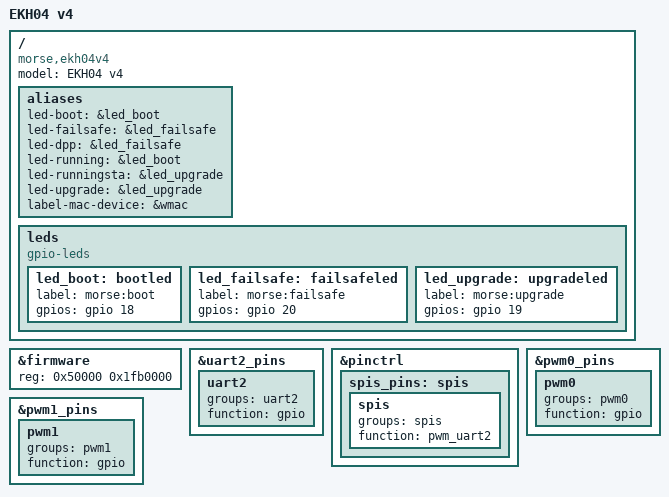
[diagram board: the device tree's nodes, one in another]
#include "mt7628an_morse_ekh03.dtsi"

/ {
	compatible = "morse,ekh04v4", "mediatek,mt7628an-soc";
	model = "EKH04 v4";

	aliases {
		led-boot = &led_boot;
		led-failsafe = &led_failsafe;
		led-dpp = &led_failsafe;
		led-running = &led_boot;
		led-runningsta = &led_upgrade;
		led-upgrade = &led_upgrade;
		label-mac-device = &wmac;
	};

	leds {
		compatible = "gpio-leds";

		led_boot: bootled {
			label = "morse:boot";
			gpios = <&gpio 18 GPIO_ACTIVE_HIGH>;
		};

		led_failsafe: failsafeled {
			label = "morse:failsafe";
			gpios = <&gpio 20 GPIO_ACTIVE_HIGH>;
		};

		led_upgrade: upgradeled {
			label = "morse:upgrade";
			gpios = <&gpio 19 GPIO_ACTIVE_HIGH>;
		};
	};
};

&firmware {
	reg = <0x50000 0x1fb0000>;
};

&uart2_pins {
	uart2 {
		groups = "uart2";
		function = "gpio";
	};
};

&pinctrl {
	spis_pins: spis{
		spis{
			groups = "spis";
			function = "pwm_uart2";
		};
	};
};

&pwm0_pins {
	pwm0 {
		groups = "pwm0";
		function = "gpio";
	};
};

&pwm1_pins {
	pwm1 {
		groups = "pwm1";
		function = "gpio";
	};
};
